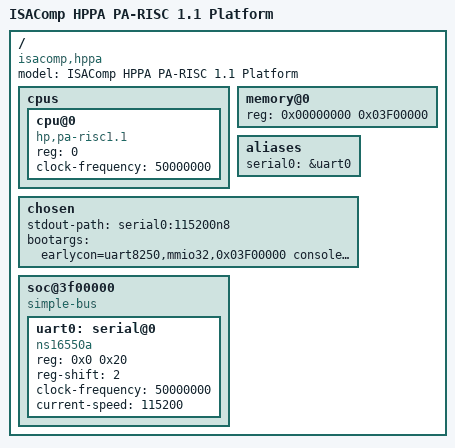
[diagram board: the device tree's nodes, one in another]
// SPDX-License-Identifier: GPL-2.0
// Device tree for HPPA (PA-RISC 1.1) processor generated by ISAComp
// Platform: Verilator simulation with NS16550A UART
/dts-v1/;

/ {
	compatible = "isacomp,hppa";
	model = "ISAComp HPPA PA-RISC 1.1 Platform";

	#address-cells = <1>;
	#size-cells = <1>;

	cpus {
		#address-cells = <1>;
		#size-cells = <0>;

		cpu@0 {
			device_type = "cpu";
			compatible = "hp,pa-risc1.1";
			reg = <0>;
			clock-frequency = <50000000>;  // 50 MHz
		};
	};

	// 63MB memory starting at physical address 0
	// 0x00000000 - 0x00000FFF: Page Zero (firmware interface)
	// 0x00001000 - 0x000FFFFF: Boot stub / firmware
	// 0x00100000 - 0x037FFFFF: Kernel image
	// 0x03800000 - 0x03EFFFFF: Initrd
	// 0x03F00000 - 0x03FFFFFF: Reserved for peripherals
	memory@0 {
		device_type = "memory";
		reg = <0x00000000 0x03F00000>;  // 63MB
	};

	aliases {
		serial0 = &uart0;
	};

	chosen {
		stdout-path = "serial0:115200n8";
		bootargs = "earlycon=uart8250,mmio32,0x03F00000 console=ttyS0,115200";
	};

	// Peripheral region: last 1MB of 64MB address space
	// 0x03F00000 - 0x03FFFFFF
	soc@3f00000 {
		compatible = "simple-bus";
		ranges = <0 0x03F00000 0x100000>;

		#address-cells = <1>;
		#size-cells = <1>;

		// NS16550A serial port
		// Word-aligned registers (reg-shift=2)
		// Linux driver: drivers/tty/serial/8250/
		uart0: serial@0 {
			compatible = "ns16550a";
			reg = <0x0 0x20>;
			reg-shift = <2>;
			clock-frequency = <50000000>;
			current-speed = <115200>;
		};

		// Note: Timer is CPU-internal (CR16 interval timer).
		// Linux/parisc reads CR16 via MFCTL for timekeeping and
		// writes MTCTL to set the interval timer match register.
		// No device tree node is needed for the timer.

		// Note: Interrupt controller is CPU-internal (EIRR/EIEM).
		// PA-RISC uses MFCTL/MTCTL on CR23 (EIRR) and CR15 (EIEM)
		// for interrupt management. External devices signal
		// interrupts by setting bits in EIRR via hardware.
	};
};
